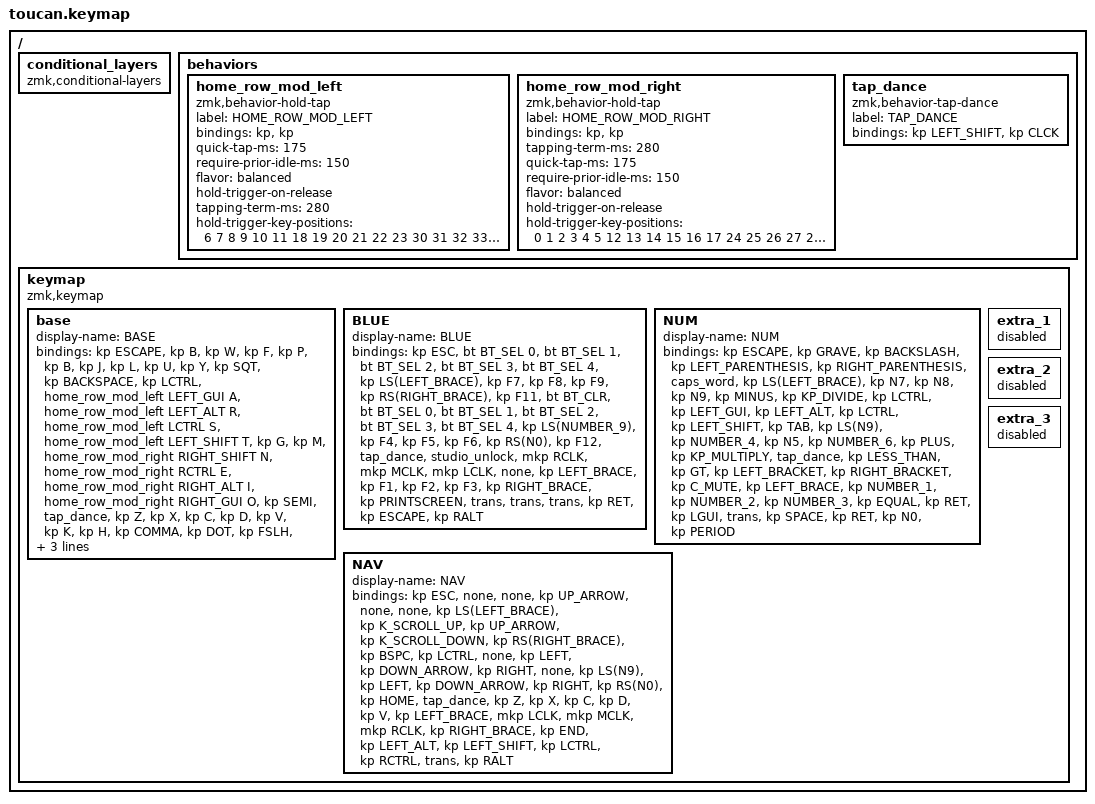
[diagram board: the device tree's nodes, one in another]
#include <behaviors.dtsi>
#include <dt-bindings/zmk/bt.h>
#include <dt-bindings/zmk/keys.h>
#include <dt-bindings/zmk/pointing.h>

#define BASE 0
#define NAV  1
#define SYM  2
#define ADJ  3

/ {
    conditional_layers { compatible = "zmk,conditional-layers"; };

    behaviors {
        home_row_mod_left: home_row_mod_left {
            compatible = "zmk,behavior-hold-tap";
            label = "HOME_ROW_MOD_LEFT";
            bindings = <&kp>, <&kp>;

            #binding-cells = <2>;
            quick-tap-ms = <175>;
            require-prior-idle-ms = <150>;
            flavor = "balanced";
            hold-trigger-on-release;
            tapping-term-ms = <280>;
            hold-trigger-key-positions = <6 7 8 9 10 11 18 19 20 21 22 23 30 31 32 33 34 35>;
        };

        home_row_mod_right: home_row_mod_right {
            compatible = "zmk,behavior-hold-tap";
            label = "HOME_ROW_MOD_RIGHT";
            bindings = <&kp>, <&kp>;

            #binding-cells = <2>;
            tapping-term-ms = <280>;
            quick-tap-ms = <175>;
            require-prior-idle-ms = <150>;
            flavor = "balanced";
            hold-trigger-on-release;
            hold-trigger-key-positions = <0 1 2 3 4 5 12 13 14 15 16 17 24 25 26 27 28 29>;
        };

        tap_dance: tap_dance {
            compatible = "zmk,behavior-tap-dance";
            label = "TAP_DANCE";
            #binding-cells = <0>;
            bindings = <&kp LEFT_SHIFT>, <&kp CLCK>;
        };
    };

    keymap {
        compatible = "zmk,keymap";

        base {
            display-name = "BASE";
            bindings = <
&kp ESCAPE  &kp B  &kp W  &kp F  &kp P  &kp B  &kp J  &kp L  &kp U  &kp Y  &kp SQT  &kp BACKSPACE  &kp LCTRL  &home_row_mod_left LEFT_GUI A  &home_row_mod_left LEFT_ALT R  &home_row_mod_left LCTRL S  &home_row_mod_left LEFT_SHIFT T  &kp G  &kp M  &home_row_mod_right RIGHT_SHIFT N  &home_row_mod_right RCTRL E  &home_row_mod_right RIGHT_ALT I  &home_row_mod_right RIGHT_GUI O  &kp SEMI  &tap_dance  &kp Z  &kp X  &kp C  &kp D  &kp V  &kp K  &kp H  &kp COMMA  &kp DOT  &kp FSLH  &kp MINUS  &lt 3 LEFT_GUI  &lt 2 SPACE  &lt 1 TAB  &lt 2 RETURN  &lt 3 BACKSPACE  &lt 1 RALT
            >;
        };

        BLUE {
            display-name = "BLUE";
            bindings = <
&kp ESC  &bt BT_SEL 0  &bt BT_SEL 1  &bt BT_SEL 2  &bt BT_SEL 3  &bt BT_SEL 4  &kp LS(LEFT_BRACE)  &kp F7  &kp F8  &kp F9  &kp RS(RIGHT_BRACE)  &kp F11  &bt BT_CLR  &bt BT_SEL 0  &bt BT_SEL 1  &bt BT_SEL 2  &bt BT_SEL 3  &bt BT_SEL 4  &kp LS(NUMBER_9)  &kp F4  &kp F5  &kp F6  &kp RS(N0)  &kp F12  &tap_dance  &studio_unlock  &mkp RCLK  &mkp MCLK  &mkp LCLK  &none  &kp LEFT_BRACE  &kp F1  &kp F2  &kp F3  &kp RIGHT_BRACE  &kp PRINTSCREEN  &trans  &trans  &trans  &kp RET  &kp ESCAPE  &kp RALT
            >;
        };

        NUM {
            display-name = "NUM";
            bindings = <
&kp ESCAPE  &kp GRAVE  &kp BACKSLASH  &kp LEFT_PARENTHESIS  &kp RIGHT_PARENTHESIS  &caps_word  &kp LS(LEFT_BRACE)  &kp N7  &kp N8  &kp N9  &kp MINUS  &kp KP_DIVIDE  &kp LCTRL  &kp LEFT_GUI  &kp LEFT_ALT  &kp LCTRL  &kp LEFT_SHIFT  &kp TAB  &kp LS(N9)  &kp NUMBER_4  &kp N5  &kp NUMBER_6  &kp PLUS  &kp KP_MULTIPLY  &tap_dance  &kp LESS_THAN  &kp GT  &kp LEFT_BRACKET  &kp RIGHT_BRACKET  &kp C_MUTE  &kp LEFT_BRACE  &kp NUMBER_1  &kp NUMBER_2  &kp NUMBER_3  &kp EQUAL  &kp RET  &kp LGUI  &trans  &kp SPACE  &kp RET  &kp N0  &kp PERIOD
            >;
        };

        NAV {
            display-name = "NAV";
            bindings = <
&kp ESC  &none  &none  &kp UP_ARROW  &none  &none  &kp LS(LEFT_BRACE)  &kp K_SCROLL_UP  &kp UP_ARROW  &kp K_SCROLL_DOWN  &kp RS(RIGHT_BRACE)  &kp BSPC  &kp LCTRL  &none  &kp LEFT  &kp DOWN_ARROW  &kp RIGHT  &none  &kp LS(N9)  &kp LEFT  &kp DOWN_ARROW  &kp RIGHT  &kp RS(N0)  &kp HOME  &tap_dance  &kp Z  &kp X  &kp C  &kp D  &kp V  &kp LEFT_BRACE  &mkp LCLK  &mkp MCLK  &mkp RCLK  &kp RIGHT_BRACE  &kp END  &kp LEFT_ALT  &kp LEFT_SHIFT  &kp LCTRL  &kp RCTRL  &trans  &kp RALT
            >;
        };

        extra_1 { status = "reserved"; };

        extra_2 { status = "reserved"; };

        extra_3 { status = "reserved"; };
    };
};
